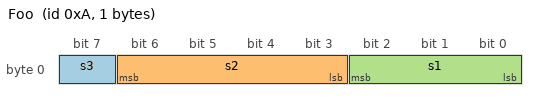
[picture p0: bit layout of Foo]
BO_ 10 Foo: 1 Vector__XXX
 SG_ s3 : 7|1@1+ (1,0) [0|0] "" Vector__XXX
 SG_ s2 : 3|4@1+ (1,0) [0|0] "" Vector__XXX
 SG_ s1 : 0|3@1+ (1,0) [0|0] "" Vector__XXX
